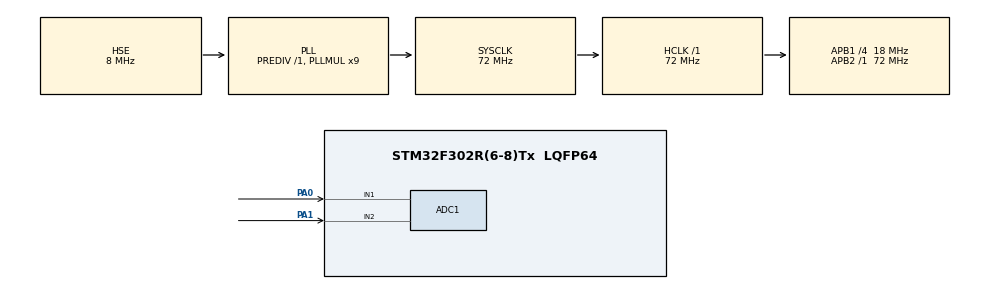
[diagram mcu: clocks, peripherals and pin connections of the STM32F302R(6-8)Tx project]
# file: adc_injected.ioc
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ADC1.Channel-1\#ChannelRegularConversion=ADC_CHANNEL_1
ADC1.ContinuousConvMode=ENABLE
ADC1.DMAContinuousRequests=DISABLE
ADC1.EOCSelection=ADC_EOC_SINGLE_CONV
ADC1.InjNumberOfConversion=1
ADC1.InjectedChannel-3\#ChannelInjectedConversion=ADC_CHANNEL_2
ADC1.InjectedOffset-3\#ChannelInjectedConversion=0
ADC1.InjectedOffsetNumber-3\#ChannelInjectedConversion=ADC_OFFSET_NONE
ADC1.InjectedRank-3\#ChannelInjectedConversion=1
ADC1.InjectedSamplingTime-3\#ChannelInjectedConversion=ADC_SAMPLETIME_19CYCLES_5
ADC1.InjectedSamplingTimeOPAMP-3\#ChannelInjectedConversion=ADC_SAMPLETIME_7CYCLES_5
ADC1.NbrOfConversionFlag=1
ADC1.Offset-1\#ChannelRegularConversion=0
ADC1.OffsetNumber-1\#ChannelRegularConversion=ADC_OFFSET_NONE
ADC1.Rank-1\#ChannelRegularConversion=1
ADC1.Rank1_Channel=ADC_CHANNEL_2
ADC1.SamplingTime-1\#ChannelRegularConversion=ADC_SAMPLETIME_19CYCLES_5
ADC1.master=1
Mcu.Family=STM32F3
Mcu.Name=STM32F302R(6-8)Tx
Mcu.Package=LQFP64
NVIC.ADC1_IRQn=true\:0\:0\:false\:false\:true\:true\:true\:true
NVIC.PriorityGroup=NVIC_PRIORITYGROUP_0
PA0.Mode=IN1-Single-Ended
PA0.Signal=ADC1_IN1
PA1.Mode=IN2-Single-Ended
PA1.Signal=ADC1_IN2
PA13.GPIO_Label=TMS
PA13.Mode=Serial_Wire
PA13.Signal=SYS_JTMS-SWDIO
PA14.GPIO_Label=TCK
PA14.Mode=Serial_Wire
PA14.Signal=SYS_JTCK-SWCLK
PB3.GPIO_Label=SWO
PB3.Mode=Trace_Asynchronous_SW
PB3.Signal=SYS_JTDO-TRACESWO
PC14\ -\ OSC32_IN.Mode=LSE-External-Oscillator
PC14\ -\ OSC32_IN.Signal=RCC_OSC32_IN
PC15\ -\ OSC32_OUT.Mode=LSE-External-Oscillator
PC15\ -\ OSC32_OUT.Signal=RCC_OSC32_OUT
PF0-OSC_IN.Mode=HSE-External-Clock-Source
PF0-OSC_IN.Signal=RCC_OSC_IN
PF1-OSC_OUT.Signal=RCC_OSC_OUT
ProjectManager.HeapSize=0x200
ProjectManager.StackSize=0x400
ProjectManager.TargetToolchain=STM32CubeIDE
RCC.ADC12PRES=RCC_ADC1PLLCLK_DIV6
RCC.AHBFreq_Value=72000000
RCC.APB1CLKDivider=RCC_HCLK_DIV4
RCC.APB1Freq_Value=18000000
RCC.APB1TimFreq_Value=36000000
RCC.APB2Freq_Value=72000000
RCC.APB2TimFreq_Value=72000000
RCC.CortexFreq_Value=72000000
RCC.HCLKFreq_Value=72000000
RCC.HSE_VALUE=8000000
RCC.HSI_VALUE=8000000
RCC.PLLM=8
RCC.PLLMUL=RCC_PLL_MUL9
RCC.PLLN=336
RCC.PLLP=RCC_PLLP_DIV4
RCC.PLLQ=7
RCC.PLLSourceVirtual=RCC_PLLSOURCE_HSE
RCC.SYSCLKFreq_VALUE=72000000
RCC.SYSCLKSourceVirtual=RCC_SYSCLKSOURCE_PLLCLK
RCC.USBFreq_Value=72000000
board=NUCLEO-F302R8

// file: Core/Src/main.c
/* USER CODE BEGIN Header */
/**
  ******************************************************************************
  * @file           : main.c
  * @brief          : Main program body
  ******************************************************************************
  * @attention
  *
  * Copyright (c) 2025 STMicroelectronics.
  * All rights reserved.
  *
  * This software is licensed under terms that can be found in the LICENSE file
  * in the root directory of this software component.
  * If no LICENSE file comes with this software, it is provided AS-IS.
  *
  ******************************************************************************
  */
/* USER CODE END Header */
#include "main.h"

ADC_HandleTypeDef hadc1;

/* USER CODE BEGIN PV */
uint16_t injected;
uint16_t regular;
float vref = 3.3;
float max_val=4095.0;
float inj_Voltage;
float reg_Voltage;

/* USER CODE END PV */

void SystemClock_Config(void);
static void MX_GPIO_Init(void);
static void MX_ADC1_Init(void);

int main(void)
{

  /* MCU Configuration--------------------------------------------------------*/

  /* Reset of all peripherals, Initializes the Flash interface and the Systick. */
  HAL_Init();

  /* Configure the system clock */
  SystemClock_Config();

  /* Initialize all configured peripherals */
  MX_GPIO_Init();
  MX_ADC1_Init();
  /* USER CODE BEGIN 2 */
  HAL_ADC_Start_IT(&hadc1);
  HAL_ADCEx_InjectedStart_IT(&hadc1);

  /* USER CODE END 2 */

  /* Infinite loop */
  while (1)
  {

    /* USER CODE BEGIN 3 */
	HAL_ADCEx_InjectedStart_IT(&hadc1);
	HAL_Delay(100);
  }
  /* USER CODE END 3 */
}

void SystemClock_Config(void)
{
  RCC_OscInitTypeDef RCC_OscInitStruct = {0};
  RCC_ClkInitTypeDef RCC_ClkInitStruct = {0};
  RCC_PeriphCLKInitTypeDef PeriphClkInit = {0};

  /** Initializes the RCC Oscillators according to the specified parameters
  * in the RCC_OscInitTypeDef structure.
  */
  RCC_OscInitStruct.OscillatorType = RCC_OSCILLATORTYPE_HSE;
  RCC_OscInitStruct.HSEState = RCC_HSE_BYPASS;
  RCC_OscInitStruct.HSEPredivValue = RCC_HSE_PREDIV_DIV1;
  RCC_OscInitStruct.HSIState = RCC_HSI_ON;
  RCC_OscInitStruct.PLL.PLLState = RCC_PLL_ON;
  RCC_OscInitStruct.PLL.PLLSource = RCC_PLLSOURCE_HSE;
  RCC_OscInitStruct.PLL.PLLMUL = RCC_PLL_MUL9;
  if (HAL_RCC_OscConfig(&RCC_OscInitStruct) != HAL_OK)
  {
    Error_Handler();
  }

  /** Initializes the CPU, AHB and APB buses clocks
  */
  RCC_ClkInitStruct.ClockType = RCC_CLOCKTYPE_HCLK|RCC_CLOCKTYPE_SYSCLK
                              |RCC_CLOCKTYPE_PCLK1|RCC_CLOCKTYPE_PCLK2;
  RCC_ClkInitStruct.SYSCLKSource = RCC_SYSCLKSOURCE_PLLCLK;
  RCC_ClkInitStruct.AHBCLKDivider = RCC_SYSCLK_DIV1;
  RCC_ClkInitStruct.APB1CLKDivider = RCC_HCLK_DIV4;
  RCC_ClkInitStruct.APB2CLKDivider = RCC_HCLK_DIV1;

  if (HAL_RCC_ClockConfig(&RCC_ClkInitStruct, FLASH_LATENCY_2) != HAL_OK)
  {
    Error_Handler();
  }
  PeriphClkInit.PeriphClockSelection = RCC_PERIPHCLK_ADC1;
  PeriphClkInit.Adc1ClockSelection = RCC_ADC1PLLCLK_DIV6;

  if (HAL_RCCEx_PeriphCLKConfig(&PeriphClkInit) != HAL_OK)
  {
    Error_Handler();
  }
}

static void MX_ADC1_Init(void)
{

  ADC_ChannelConfTypeDef sConfig = {0};
  ADC_InjectionConfTypeDef sConfigInjected = {0};

  /** Common config
  */
  hadc1.Instance = ADC1;
  hadc1.Init.ClockPrescaler = ADC_CLOCK_ASYNC_DIV1;
  hadc1.Init.Resolution = ADC_RESOLUTION_12B;
  hadc1.Init.ScanConvMode = ADC_SCAN_DISABLE;
  hadc1.Init.ContinuousConvMode = ENABLE;
  hadc1.Init.DiscontinuousConvMode = DISABLE;
  hadc1.Init.ExternalTrigConvEdge = ADC_EXTERNALTRIGCONVEDGE_NONE;
  hadc1.Init.ExternalTrigConv = ADC_SOFTWARE_START;
  hadc1.Init.DataAlign = ADC_DATAALIGN_RIGHT;
  hadc1.Init.NbrOfConversion = 1;
  hadc1.Init.DMAContinuousRequests = DISABLE;
  hadc1.Init.EOCSelection = ADC_EOC_SINGLE_CONV;
  hadc1.Init.LowPowerAutoWait = DISABLE;
  hadc1.Init.Overrun = ADC_OVR_DATA_OVERWRITTEN;
  if (HAL_ADC_Init(&hadc1) != HAL_OK)
  {
    Error_Handler();
  }

  /** Configure Regular Channel
  */
  sConfig.Channel = ADC_CHANNEL_1;
  sConfig.Rank = ADC_REGULAR_RANK_1;
  sConfig.SingleDiff = ADC_SINGLE_ENDED;
  sConfig.SamplingTime = ADC_SAMPLETIME_19CYCLES_5;
  sConfig.OffsetNumber = ADC_OFFSET_NONE;
  sConfig.Offset = 0;
  if (HAL_ADC_ConfigChannel(&hadc1, &sConfig) != HAL_OK)
  {
    Error_Handler();
  }

  /** Configure Injected Channel
  */
  sConfigInjected.InjectedChannel = ADC_CHANNEL_2;
  sConfigInjected.InjectedRank = ADC_INJECTED_RANK_1;
  sConfigInjected.InjectedSingleDiff = ADC_SINGLE_ENDED;
  sConfigInjected.InjectedNbrOfConversion = 1;
  sConfigInjected.InjectedSamplingTime = ADC_SAMPLETIME_19CYCLES_5;
  sConfigInjected.ExternalTrigInjecConvEdge = ADC_EXTERNALTRIGINJECCONV_EDGE_RISING;
  sConfigInjected.ExternalTrigInjecConv = ADC_INJECTED_SOFTWARE_START;
  sConfigInjected.AutoInjectedConv = DISABLE;
  sConfigInjected.InjectedDiscontinuousConvMode = DISABLE;
  sConfigInjected.QueueInjectedContext = DISABLE;
  sConfigInjected.InjectedOffset = 0;
  sConfigInjected.InjectedOffsetNumber = ADC_OFFSET_NONE;
  if (HAL_ADCEx_InjectedConfigChannel(&hadc1, &sConfigInjected) != HAL_OK)
  {
    Error_Handler();
  }

}

static void MX_GPIO_Init(void)
{

  /* GPIO Ports Clock Enable */
  __HAL_RCC_GPIOC_CLK_ENABLE();
  __HAL_RCC_GPIOF_CLK_ENABLE();
  __HAL_RCC_GPIOA_CLK_ENABLE();
  __HAL_RCC_GPIOB_CLK_ENABLE();

}

/* USER CODE BEGIN 4 */
void HAL_ADC_ConvCpltCallback(ADC_HandleTypeDef* hadc)
{
	regular = HAL_ADC_GetValue(hadc);
	reg_Voltage = (regular/max_val)* vref;
}

void HAL_ADCEx_InjectedConvCpltCallback(ADC_HandleTypeDef* hadc)
{

  injected = HAL_ADCEx_InjectedGetValue(hadc, ADC_INJECTED_RANK_1);
  inj_Voltage = (injected/max_val)*vref ;

}

/* USER CODE END 4 */

void Error_Handler(void)
{
  __disable_irq();
  while (1)
  {
  }
}
